# GD32F527 register map
File version: 1.0
CPU: CM33 r0p1, little endian, MPU, FPU, 4 interrupt priority bits
Registers are 32-bit, read-write, reset 0x0 unless marked. A register's access mark holds for its fields unless they carry their own. Offsets are from the block's base; [hi:lo] are bit positions; {n}, {i} and the like mark numbered series.

## CAU — Cryptographic Acceleration Unit
Base 0x50060000
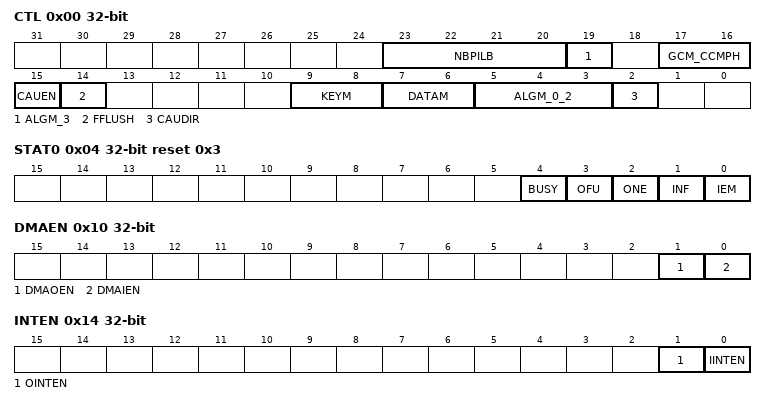
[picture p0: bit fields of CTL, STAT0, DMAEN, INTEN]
0x00 CTL access per field — Control register
  [23:20] NBPILB rw — Number of bytes padding in last block of payload
  [19] ALGM_3 rw — Encryption/decryption algorithm mode bit 3
  [17:16] GCM_CCMPH rw — GCM CCM phase
  [15] CAUEN rw — CAU Enable
  [14] FFLUSH wo — Flush FIFO
  [9:8] KEYM rw — AES key size mode configuration, must be configured when BUSY=0
  [7:6] DATAM rw — Data swapping type mode configuration, must be configured when BUSY=0
  [5:3] ALGM_0_2 rw — Encryption/decryption algorithm mode bit 0 to bit 2
  [2] CAUDIR rw — CAU direction, must be configured when BUSY=0
0x04 STAT0 ro reset 0x3 — Status register 0
  [4] BUSY — Busy bit
  [3] OFU — Output FIFO is full
  [2] ONE — Output FIFO is not empty
  [1] INF — Input FIFO is not full
  [0] IEM — Input FIFO is empty
0x08 DI — Data input register
  [31:0] DI — Data input
0x0C DO ro — Data output register
  [31:0] DO — Data output
0x10 DMAEN — DMA enable register
  [1] DMAOEN — DMA output enable
  [0] DMAIEN — DMA input enable
0x14 INTEN — Interrupt enable register
  [1] OINTEN — OUT FIFO interrupt enable
  [0] IINTEN — IN FIFO interrupt enable
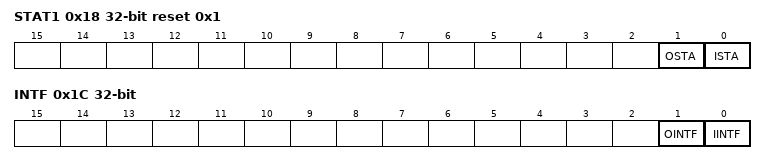
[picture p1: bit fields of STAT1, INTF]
0x18 STAT1 ro reset 0x1 — Status register 1
  [1] OSTA — OUT FIFO interrupt status
  [0] ISTA — IN FIFO interrupt status
0x1C INTF ro — Interrupt flag register
  [1] OINTF — OUT FIFO enabled interrupt flag
  [0] IINTF — IN FIFO enabled interrupt flag
{0x20+8i} KEY{i}H wo (i=0..3) — KEY{i} high register
  [31:0] KEY{i}H — The key for DES, TDES, AES
{0x24+8i} KEY{i}L wo (i=0..3) — KEY{i} low register
  [31:0] KEY{i}L — The key for DES, TDES, AES
0x40 IV0H — Initial vector registers 0 high
  [31:0] IV0H — The initialization vector for DES, TDES, AES
0x44 IV0L — Initial vector registers 0 low
  [31:0] IV0L — The initialization vector for DES, TDES, AES
0x48 IV1H — Initial vector registers 1 high
  [31:0] IV1H — The initialization vector for DES, TDES, AES
0x4C IV1L — Initial vector registers 1 low
  [31:0] IV1L — The initialization vector for DES, TDES, AES
{0x50+4i} GCMCCMCTXS{i} (i=0..7) — GCM or CCM mode context switch register {i}
  [31:0] CTXx — The internal status of the CAU core
{0x70+4i} GCMCTXS{i} (i=0..7) — GCM mode context switch register {i}
  [31:0] CTXx — The internal status of the CAU core

## CRC — Cyclic redundancy checks management unit
Base 0x40023000
0x00 DATA reset 0xFFFFFFFF
  [31:0] DATA — CRC calculation result bits
0x04 FDATA — Free data register
  [7:0] FDATA — Free Data Register bits
0x08 CTL — Control register
  [0] RST — Set this bit can reset the CRC_DATA register to the value of 0xFFFFFFFF then automatically cleared itself to 0 by hardware. This bit will take no effect to CRC_FDATA.

## CTC — Clock trim controller
Base 0x40006C00
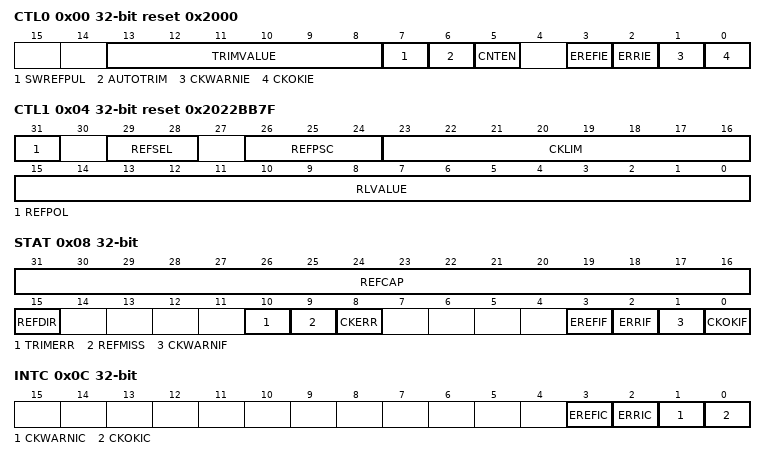
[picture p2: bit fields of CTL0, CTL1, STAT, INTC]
0x00 CTL0 access per field reset 0x2000 — Control register 0
  [13:8] TRIMVALUE rw — IRC48M trim value
  [7] SWREFPUL wo — Software reference source sync pulse
  [6] AUTOTRIM rw — Hardware automatic trim mode
  [5] CNTEN rw — CTC counter enable
  [3] EREFIE rw — Expected reference (EREFIF) interrupt enable
  [2] ERRIE rw — Error (ERRIF) interrupt enable
  [1] CKWARNIE rw — Clock trim warning (CKWARNIF) interrupt enable
  [0] CKOKIE rw — Clock trim ok (CKOKIF) interrupt enable
0x04 CTL1 reset 0x2022BB7F — Control register 1
  [31] REFPOL — Reference signal source polarity
  [29:28] REFSEL — Reference signal source selection
  [26:24] REFPSC — Reference signal source prescaler
  [23:16] CKLIM — Clock trim base limit value
  [15:0] RLVALUE — CTC counter reload value
0x08 STAT ro — Status register
  [31:16] REFCAP — CTC counter capture value.
  [15] REFDIR — CTC trim counter direction
  [10] TRIMERR — Trim value error bit
  [9] REFMISS — Reference sync pulse miss
  [8] CKERR — Clock trim error bit
  [3] EREFIF — Expected reference interrupt flag
  [2] ERRIF — Error interrupt flag
  [1] CKWARNIF — Clock trim warning interrupt flag
  [0] CKOKIF — Clock trim OK interrupt flag
0x0C INTC wo — Interrupt clear register
  [3] EREFIC — EREFIF interrupt clear bit
  [2] ERRIC — ERRIF interrupt clear bit
  [1] CKWARNIC — CKWARNIF interrupt clear bit
  [0] CKOKIC — CKOKIF interrupt clear bit
